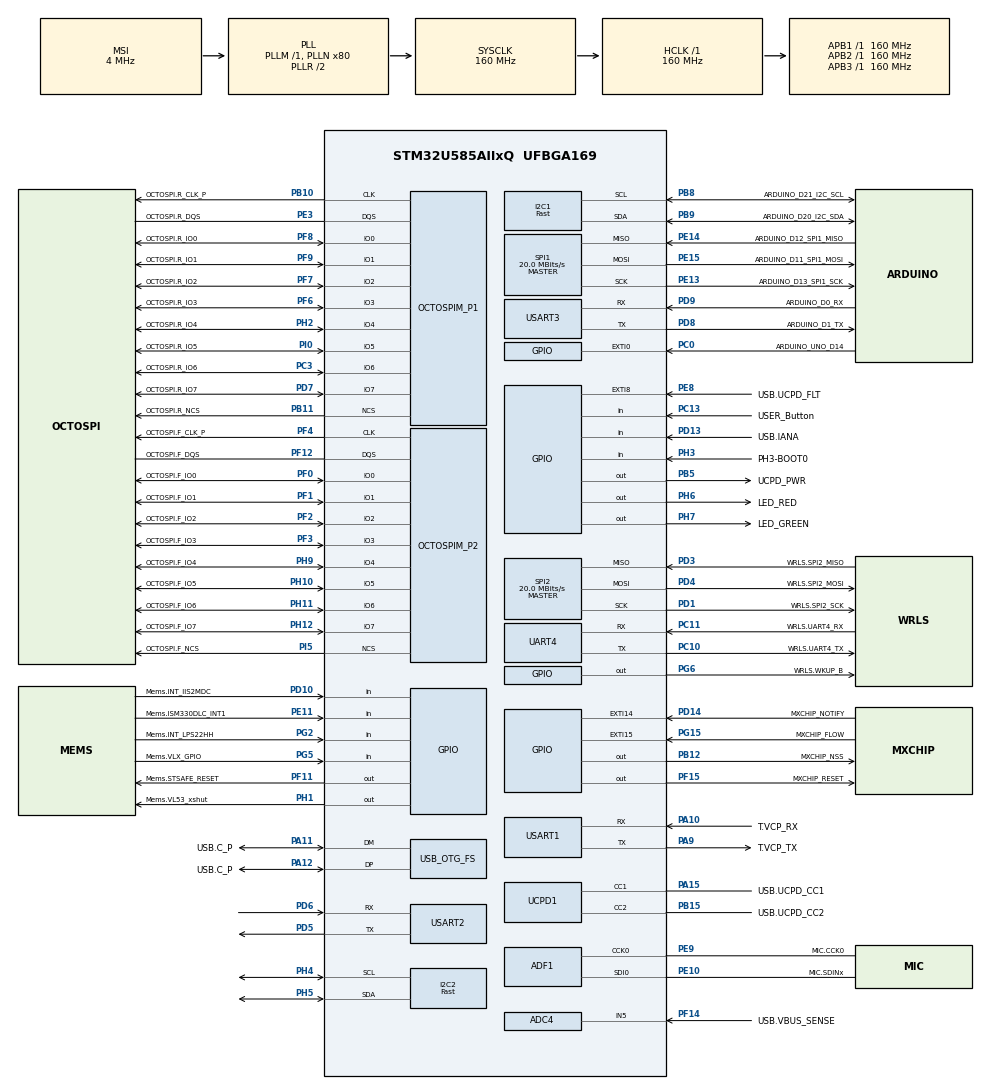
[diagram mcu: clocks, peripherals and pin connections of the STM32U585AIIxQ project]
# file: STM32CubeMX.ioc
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ADC4.NbrOfConversion=1
ADC4.NbrOfConversionFlag=0
ADC4.SelectedChannel=ADC_CHANNEL_5
CORTEX_M33_NS.userName=CORTEX_M33
GPDMA1.DESTINC_GPDMACH2=DMA_DINC_INCREMENTED
GPDMA1.DESTINC_GPDMACH4=DMA_DINC_INCREMENTED
GPDMA1.DESTINC_GPDMACH8=DMA_DINC_INCREMENTED
GPDMA1.DIRECTION_GPDMACH3=DMA_MEMORY_TO_PERIPH
GPDMA1.DIRECTION_GPDMACH5=DMA_MEMORY_TO_PERIPH
GPDMA1.DIRECTION_GPDMACH9=DMA_MEMORY_TO_PERIPH
GPDMA1.IPHANDLE_GPDMACH2-SIMPLEREQUEST_GPDMACH2=__NULL
GPDMA1.IPHANDLE_GPDMACH3-SIMPLEREQUEST_GPDMACH3=__NULL
GPDMA1.IPHANDLE_GPDMACH4-SIMPLEREQUEST_GPDMACH4=__NULL
GPDMA1.IPHANDLE_GPDMACH5-SIMPLEREQUEST_GPDMACH5=__NULL
GPDMA1.IPHANDLE_GPDMACH8-SIMPLEREQUEST_GPDMACH8=__NULL
GPDMA1.IPHANDLE_GPDMACH9-SIMPLEREQUEST_GPDMACH9=__NULL
GPDMA1.PRIORITY_GPDMACH2=DMA_LOW_PRIORITY_HIGH_WEIGHT
GPDMA1.PRIORITY_GPDMACH3=DMA_LOW_PRIORITY_HIGH_WEIGHT
GPDMA1.PRIORITY_GPDMACH4=DMA_LOW_PRIORITY_HIGH_WEIGHT
GPDMA1.PRIORITY_GPDMACH5=DMA_LOW_PRIORITY_HIGH_WEIGHT
GPDMA1.PRIORITY_GPDMACH8=DMA_LOW_PRIORITY_HIGH_WEIGHT
GPDMA1.PRIORITY_GPDMACH9=DMA_LOW_PRIORITY_HIGH_WEIGHT
GPDMA1.REQUEST_GPDMACH2=GPDMA1_REQUEST_SPI1_RX
GPDMA1.REQUEST_GPDMACH3=GPDMA1_REQUEST_SPI1_TX
GPDMA1.REQUEST_GPDMACH4=GPDMA1_REQUEST_SPI2_RX
GPDMA1.REQUEST_GPDMACH5=GPDMA1_REQUEST_SPI2_TX
GPDMA1.REQUEST_GPDMACH8=GPDMA1_REQUEST_USART3_RX
GPDMA1.REQUEST_GPDMACH9=GPDMA1_REQUEST_USART3_TX
GPDMA1.SRCINC_GPDMACH3=DMA_SINC_INCREMENTED
GPDMA1.SRCINC_GPDMACH5=DMA_SINC_INCREMENTED
GPDMA1.SRCINC_GPDMACH9=DMA_SINC_INCREMENTED
GPDMA1.TRANSFERALLOCATEDPORTDEST_GPDMACH2=DMA_DEST_ALLOCATED_PORT1
GPDMA1.TRANSFERALLOCATEDPORTDEST_GPDMACH4=DMA_DEST_ALLOCATED_PORT1
GPDMA1.TRANSFERALLOCATEDPORTDEST_GPDMACH8=DMA_DEST_ALLOCATED_PORT1
GPDMA1.TRANSFERALLOCATEDPORTSRC_GPDMACH2=DMA_SRC_ALLOCATED_PORT1
GPDMA1.TRANSFERALLOCATEDPORTSRC_GPDMACH4=DMA_SRC_ALLOCATED_PORT1
GPDMA1.TRANSFERALLOCATEDPORTSRC_GPDMACH8=DMA_SRC_ALLOCATED_PORT1
I2C1.I2C_Speed_Mode=I2C_Fast
I2C1.Timing=0x00F07BFF
I2C2.I2C_Speed_Mode=I2C_Fast
I2C2.Timing=0x00F07BFF
Mcu.Family=STM32U5
Mcu.Name=STM32U585AIIxQ
Mcu.Package=UFBGA169
NVIC.EXTI0_IRQn=true\:8\:0\:true\:false\:true\:true\:true\:true
NVIC.EXTI14_IRQn=true\:8\:0\:true\:false\:true\:true\:true\:true
NVIC.EXTI15_IRQn=true\:8\:0\:true\:false\:true\:true\:true\:true
NVIC.EXTI8_IRQn=true\:8\:0\:true\:false\:true\:true\:true\:true
NVIC.GPDMA1_Channel2_IRQn=true\:8\:0\:true\:false\:true\:false\:true\:true
NVIC.GPDMA1_Channel3_IRQn=true\:8\:0\:true\:false\:true\:false\:true\:true
NVIC.GPDMA1_Channel4_IRQn=true\:8\:0\:true\:false\:true\:false\:true\:true
NVIC.GPDMA1_Channel5_IRQn=true\:8\:0\:true\:false\:true\:false\:true\:true
NVIC.GPDMA1_Channel8_IRQn=true\:8\:0\:true\:false\:true\:false\:true\:true
NVIC.GPDMA1_Channel9_IRQn=true\:8\:0\:true\:false\:true\:false\:true\:true
NVIC.I2C1_ER_IRQn=true\:8\:0\:true\:false\:true\:true\:true\:true
NVIC.I2C1_EV_IRQn=true\:8\:0\:true\:false\:true\:true\:true\:true
NVIC.OTG_FS_IRQn=true\:8\:0\:true\:false\:true\:true\:true\:true
NVIC.PriorityGroup=NVIC_PRIORITYGROUP_4
NVIC.SPI1_IRQn=true\:8\:0\:true\:false\:true\:true\:true\:true
NVIC.SPI2_IRQn=true\:8\:0\:true\:false\:true\:true\:true\:true
NVIC.TIM17_IRQn=true\:15\:0\:false\:false\:true\:false\:true\:true
NVIC.TimeBase=TIM17_IRQn
NVIC.TimeBaseIP=TIM17
NVIC.USART1_IRQn=true\:8\:0\:true\:false\:true\:true\:true\:true
NVIC.USART2_IRQn=true\:8\:0\:true\:false\:true\:true\:true\:true
NVIC.USART3_IRQn=true\:8\:0\:true\:false\:true\:true\:true\:true
OCTOSPI1.ChipSelectBoundary=10
OCTOSPI1.ClockPrescaler=2
OCTOSPI1.DelayBlockBypass=HAL_OSPI_DELAY_BLOCK_USED
OCTOSPI1.DelayHoldQuarterCycle=HAL_OSPI_DHQC_ENABLE
OCTOSPI1.DeviceSize=23
OCTOSPI1.MemoryType=HAL_OSPI_MEMTYPE_APMEMORY
OCTOSPI1.Refresh=100
OCTOSPI2.ChipSelectBoundary=0
OCTOSPI2.ChipSelectHighTime=2
OCTOSPI2.ClockPrescaler=4
OCTOSPI2.DelayBlockBypass=HAL_OSPI_DELAY_BLOCK_USED
OCTOSPI2.DelayHoldQuarterCycle=HAL_OSPI_DHQC_ENABLE
OCTOSPI2.DeviceSize=26
OCTOSPI2.FifoThreshold=4
OCTOSPI2.MemoryType=HAL_OSPI_MEMTYPE_MACRONIX
PA10.GPIO_Label=T.VCP_RX
PA10.Mode=Asynchronous
PA10.Signal=USART1_RX
PA11.GPIO_Label=USB.C_P
PA11.GPIO_Speed=GPIO_SPEED_FREQ_HIGH
PA11.Mode=Host_Only
PA11.Signal=USB_OTG_FS_DM
PA12.GPIO_Label=USB.C_P
PA12.GPIO_Speed=GPIO_SPEED_FREQ_HIGH
PA12.Mode=Host_Only
PA12.Signal=USB_OTG_FS_DP
PA13\ (JTMS/SWDIO).GPIO_Label=T.SWDIO
PA13\ (JTMS/SWDIO).Mode=Trace_Asynchronous_SW
PA13\ (JTMS/SWDIO).Signal=DEBUG_JTMS-SWDIO
PA14\ (JTCK/SWCLK).GPIO_Label=T.SWCLK
PA14\ (JTCK/SWCLK).Mode=Trace_Asynchronous_SW
PA14\ (JTCK/SWCLK).Signal=DEBUG_JTCK-SWCLK
PA15\ (JTDI).GPIO_Label=USB.UCPD_CC1
PA15\ (JTDI).Mode=Dual_Role_AllSignals
PA15\ (JTDI).Signal=UCPD1_CC1
PA9.GPIO_Label=T.VCP_TX
PA9.Mode=Asynchronous
PA9.Signal=USART1_TX
PB1.GPIO_Label=MIC.SDIN0
PB1.Signal=MDF1_SDI0
PB10.GPIO_Label=OCTOSPI.R_CLK_P
PB10.Mode=O1_P1_CLK
PB10.Signal=OCTOSPIM_P1_CLK
PB11.GPIO_Label=OCTOSPI.R_NCS
PB11.Mode=OCTOSPI1_Port1_NCS
PB11.Signal=OCTOSPIM_P1_NCS
PB12.GPIO_Label=MXCHIP_NSS
PB12.GPIO_Speed=GPIO_SPEED_FREQ_HIGH
PB12.PinState=GPIO_PIN_SET
PB12.Signal=GPIO_Output
PB15.GPIO_Label=USB.UCPD_CC2
PB15.Mode=Dual_Role_AllSignals
PB15.Signal=UCPD1_CC2
PB3\ (JTDO/TRACESWO).GPIO_Label=T.SWO
PB3\ (JTDO/TRACESWO).Mode=Trace_Asynchronous_SW
PB3\ (JTDO/TRACESWO).Signal=DEBUG_JTDO-SWO
PB5.GPIO_Label=UCPD_PWR
PB5.Signal=GPIO_Output
PB8.GPIO_Label=ARDUINO_D21_I2C_SCL
PB8.GPIO_Pu=GPIO_NOPULL
PB8.GPIO_Speed=GPIO_SPEED_FREQ_LOW
PB8.Mode=I2C
PB8.Signal=I2C1_SCL
PB9.GPIO_Label=ARDUINO_D20_I2C_SDA
PB9.GPIO_Pu=GPIO_NOPULL
PB9.GPIO_Speed=GPIO_SPEED_FREQ_LOW
PB9.Mode=I2C
PB9.Signal=I2C1_SDA
PC0.GPIO_Label=ARDUINO_UNO_D14
PC0.Signal=GPXTI0
PC10.GPIO_Label=WRLS.UART4_TX
PC10.Mode=Asynchronous
PC10.Signal=UART4_TX
PC11.GPIO_Label=WRLS.UART4_RX
PC11.Mode=Asynchronous
PC11.Signal=UART4_RX
PC13.GPIO_Label=USER_Button
PC13.Signal=GPIO_Input
PC14-OSC32_IN\ (PC14).GPIO_Label=PC14-OSC32_IN
PC14-OSC32_IN\ (PC14).Mode=LSE-External-Oscillator
PC14-OSC32_IN\ (PC14).Signal=RCC_OSC32_IN
PC15-OSC32_OUT\ (PC15).GPIO_Label=PC15-OSC32_OUT
PC15-OSC32_OUT\ (PC15).Mode=LSE-External-Oscillator
PC15-OSC32_OUT\ (PC15).Signal=RCC_OSC32_OUT
PC3.GPIO_Label=OCTOSPI.R_IO6
PC3.Mode=OCTOSPI1_IOH_Port1H
PC3.Signal=OCTOSPIM_P1_IO6
PD1.GPIO_Label=WRLS.SPI2_SCK
PD1.GPIO_Speed=GPIO_SPEED_FREQ_HIGH
PD1.Mode=Full_Duplex_Master
PD1.Signal=SPI2_SCK
PD10.GPIO_Label=Mems.INT_IIS2MDC
PD10.Signal=GPIO_Input
PD13.GPIO_Label=USB.IANA
PD13.Signal=GPIO_Input
PD14.GPIO_Label=MXCHIP_NOTIFY
PD14.Signal=GPXTI14
PD3.GPIO_Label=WRLS.SPI2_MISO
PD3.GPIO_Speed=GPIO_SPEED_FREQ_HIGH
PD3.Mode=Full_Duplex_Master
PD3.Signal=SPI2_MISO
PD4.GPIO_Label=WRLS.SPI2_MOSI
PD4.GPIO_Speed=GPIO_SPEED_FREQ_HIGH
PD4.Mode=Full_Duplex_Master
PD4.Signal=SPI2_MOSI
PD5.Mode=Asynchronous
PD5.Signal=USART2_TX
PD6.Mode=Asynchronous
PD6.Signal=USART2_RX
PD7.GPIO_Label=OCTOSPI.R_IO7
PD7.Mode=OCTOSPI1_IOH_Port1H
PD7.Signal=OCTOSPIM_P1_IO7
PD8.GPIO_Label=ARDUINO_D1_TX
PD8.GPIO_Speed=GPIO_SPEED_FREQ_MEDIUM
PD8.Mode=Asynchronous
PD8.Signal=USART3_TX
PD9.GPIO_Label=ARDUINO_D0_RX
PD9.GPIO_Speed=GPIO_SPEED_FREQ_MEDIUM
PD9.Mode=Asynchronous
PD9.Signal=USART3_RX
PE10.GPIO_Label=MIC.SDINx
PE10.Mode=MOD_ADF_CCK
PE10.Signal=ADF1_SDI0
PE11.GPIO_Label=Mems.ISM330DLC_INT1
PE11.Signal=GPIO_Input
PE13.GPIO_Label=ARDUINO_D13_SPI1_SCK
PE13.GPIO_Speed=GPIO_SPEED_FREQ_HIGH
PE13.Mode=Full_Duplex_Master
PE13.Signal=SPI1_SCK
PE14.GPIO_Label=ARDUINO_D12_SPI1_MISO
PE14.GPIO_Speed=GPIO_SPEED_FREQ_HIGH
PE14.Mode=Full_Duplex_Master
PE14.Signal=SPI1_MISO
PE15.GPIO_Label=ARDUINO_D11_SPI1_MOSI
PE15.GPIO_Speed=GPIO_SPEED_FREQ_HIGH
PE15.Mode=Full_Duplex_Master
PE15.Signal=SPI1_MOSI
PE3.GPIO_Label=OCTOSPI.R_DQS
PE3.Mode=OCTOSPI1_Port1_DQS
PE3.Signal=OCTOSPIM_P1_DQS
PE8.GPIO_Label=USB.UCPD_FLT
PE8.GPIO_ModeDefaultEXTI=GPIO_MODE_IT_FALLING
PE8.GPIO_PuPd=GPIO_PULLUP
PE8.Signal=GPXTI8
PE9.GPIO_Label=MIC.CCK0
PE9.Mode=MOD_MDF_CCK0
PE9.Signal=ADF1_CCK0
PF0.GPIO_Label=OCTOSPI.F_IO0
PF0.Mode=OCTOSPI2_IOL_Port2L
PF0.Signal=OCTOSPIM_P2_IO0
PF1.GPIO_Label=OCTOSPI.F_IO1
PF1.Mode=OCTOSPI2_IOL_Port2L
PF1.Signal=OCTOSPIM_P2_IO1
PF10.GPIO_Label=MIC.CCK1
PF10.Signal=MDF1_CCK1
PF11.GPIO_Label=Mems.STSAFE_RESET
PF11.Signal=GPIO_Output
PF12.GPIO_Label=OCTOSPI.F_DQS
PF12.Mode=OCTOSPI2_Port2_DQS
PF12.Signal=OCTOSPIM_P2_DQS
PF14.GPIO_Label=USB.VBUS_SENSE
PF14.Signal=SharedAnalog_PF14
PF15.GPIO_Label=MXCHIP_RESET
PF15.Signal=GPIO_Output
PF2.GPIO_Label=OCTOSPI.F_IO2
PF2.Mode=OCTOSPI2_IOL_Port2L
PF2.Signal=OCTOSPIM_P2_IO2
PF3.GPIO_Label=OCTOSPI.F_IO3
PF3.Mode=OCTOSPI2_IOL_Port2L
PF3.Signal=OCTOSPIM_P2_IO3
PF4.GPIO_Label=OCTOSPI.F_CLK_P
PF4.Mode=O2_P2_CLK
PF4.Signal=OCTOSPIM_P2_CLK
PF6.GPIO_Label=OCTOSPI.R_IO3
PF6.Mode=OCTOSPI1_IOL_Port1L
PF6.Signal=OCTOSPIM_P1_IO3
PF7.GPIO_Label=OCTOSPI.R_IO2
PF7.Mode=OCTOSPI1_IOL_Port1L
PF7.Signal=OCTOSPIM_P1_IO2
PF8.GPIO_Label=OCTOSPI.R_IO0
PF8.Mode=OCTOSPI1_IOL_Port1L
PF8.Signal=OCTOSPIM_P1_IO0
PF9.GPIO_Label=OCTOSPI.R_IO1
PF9.Mode=OCTOSPI1_IOL_Port1L
PF9.Signal=OCTOSPIM_P1_IO1
PG15.GPIO_Label=MXCHIP_FLOW
PG15.Signal=GPXTI15
PG2.GPIO_Label=Mems.INT_LPS22HH
PG2.Signal=GPIO_Input
PG5.GPIO_Label=Mems.VLX_GPIO
PG5.Signal=GPIO_Input
PG6.GPIO_Label=WRLS.WKUP_B
PG6.Signal=GPIO_Output
PH1-OSC_OUT\ (PH1).GPIO_Label=Mems.VL53_xshut
PH1-OSC_OUT\ (PH1).Signal=GPIO_Output
PH10.GPIO_Label=OCTOSPI.F_IO5
PH10.Mode=OCTOSPI2_IOH_Port2H
PH10.Signal=OCTOSPIM_P2_IO5
PH11.GPIO_Label=OCTOSPI.F_IO6
PH11.Mode=OCTOSPI2_IOH_Port2H
PH11.Signal=OCTOSPIM_P2_IO6
PH12.GPIO_Label=OCTOSPI.F_IO7
PH12.Mode=OCTOSPI2_IOH_Port2H
PH12.Signal=OCTOSPIM_P2_IO7
PH2.GPIO_Label=OCTOSPI.R_IO4
PH2.Mode=OCTOSPI1_IOH_Port1H
PH2.Signal=OCTOSPIM_P1_IO4
PH3-BOOT0.GPIO_Label=PH3-BOOT0
PH3-BOOT0.Signal=GPIO_Input
PH4.Mode=I2C
PH4.Signal=I2C2_SCL
PH5.Mode=I2C
PH5.Signal=I2C2_SDA
PH6.GPIO_Label=LED_RED
PH6.Signal=GPIO_Output
PH7.GPIO_Label=LED_GREEN
PH7.Signal=GPIO_Output
PH9.GPIO_Label=OCTOSPI.F_IO4
PH9.Mode=OCTOSPI2_IOH_Port2H
PH9.Signal=OCTOSPIM_P2_IO4
PI0.GPIO_Label=OCTOSPI.R_IO5
PI0.Mode=OCTOSPI1_IOH_Port1H
PI0.Signal=OCTOSPIM_P1_IO5
PI5.GPIO_Label=OCTOSPI.F_NCS
PI5.Mode=OCTOSPI2_Port2_NCS
PI5.Signal=OCTOSPIM_P2_NCS
PWR.PowerMode=PWR_SMPS_SUPPLY
ProjectManager.HeapSize=0x10000
ProjectManager.StackSize=0x400
ProjectManager.TargetToolchain=STM32CubeIDE
RCC.ADCFreq_Value=16000000
RCC.AHBFreq_Value=160000000
RCC.APB1Freq_Value=160000000
RCC.APB1TimFreq_Value=160000000
RCC.APB2Freq_Value=160000000
RCC.APB2TimFreq_Value=160000000
RCC.APB3Freq_Value=160000000
RCC.AdfClockSelection=RCC_ADF1CLKSOURCE_PLL3
RCC.CortexFreq_Value=160000000
RCC.DACCLockSelectionVirtual=RCC_DAC1CLKSOURCE_LSI
RCC.EPOD_VALUE=4000000
RCC.HCLKFreq_Value=160000000
RCC.HSE_VALUE=16000000
RCC.HSI48_VALUE=48000000
RCC.HSI_VALUE=16000000
RCC.LSIDIV_VALUE=32000
RCC.MSI_VALUE=4000000
RCC.PLL3N=80
RCC.PLL3Q=28
RCC.PLLN=80
RCC.SYSCLKFreq_VALUE=160000000
RCC.SYSCLKSource=RCC_SYSCLKSOURCE_PLLCLK
RCC.USBFreq_Value=48000000
RCC.VCOOutputFreq_Value=320000000
SH.SharedAnalog_PF14.0=GPIO_Analog
SH.SharedAnalog_PF14.1=ADC4_IN5,IN5
SPI1.BaudRatePrescaler=SPI_BAUDRATEPRESCALER_8
SPI1.CalculateBaudRate=20.0 MBits/s
SPI1.DataSize=SPI_DATASIZE_8BIT
SPI1.Direction=SPI_DIRECTION_2LINES
SPI1.Mode=SPI_MODE_MASTER
SPI1.NSSPMode=SPI_NSS_PULSE_DISABLE
SPI1.VirtualType=VM_MASTER
SPI2.BaudRatePrescaler=SPI_BAUDRATEPRESCALER_8
SPI2.CalculateBaudRate=20.0 MBits/s
SPI2.DataSize=SPI_DATASIZE_8BIT
SPI2.Direction=SPI_DIRECTION_2LINES
SPI2.Mode=SPI_MODE_MASTER
SPI2.NSSPMode=SPI_NSS_PULSE_DISABLE
SPI2.VirtualType=VM_MASTER
USART1.VirtualMode-Asynchronous=VM_ASYNC
USART2.VirtualMode-Asynchronous=VM_ASYNC
USART3.VirtualMode-Asynchronous=VM_ASYNC
USB_OTG_FS.VirtualMode=Host_Only
USB_OTG_FS.phy_itface=HCD_PHY_EMBEDDED
VP_GPDMA1_VS_GPDMACH2.Mode=SIMPLEREQUEST_GPDMACH2
VP_GPDMA1_VS_GPDMACH3.Mode=SIMPLEREQUEST_GPDMACH3
VP_GPDMA1_VS_GPDMACH4.Mode=SIMPLEREQUEST_GPDMACH4
VP_GPDMA1_VS_GPDMACH5.Mode=SIMPLEREQUEST_GPDMACH5
VP_GPDMA1_VS_GPDMACH8.Mode=SIMPLEREQUEST_GPDMACH8
VP_GPDMA1_VS_GPDMACH9.Mode=SIMPLEREQUEST_GPDMACH9
VP_ICACHE_VS_ICACHE.Mode=DefaultMode
VP_LPBAMQUEUE_VS_QUEUE.Mode=QUEUEMODE
VP_LPBAM_VS_SIG1.Mode=SmartRun
VP_LPBAM_VS_SIG4.Mode=LPDMA1
VP_MEMORYMAP_VS_MEMORYMAP.Mode=CurAppReg
VP_OCTOSPI1_VS_octo.Mode=octo_mode
VP_OCTOSPI2_VS_octo.Mode=octo_mode
VP_PWR_VS_DBSignals.Mode=DisableDeadBatterySignals
VP_PWR_VS_LPOM.Mode=PowerOptimisation
VP_PWR_VS_SECSignals.Mode=Security/Privilege
VP_PWR_Vdda.Mode=isolationVdda
VP_SYS_VS_tim17.Mode=TIM17
board=B-U585I-IOT02A

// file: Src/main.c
/* USER CODE BEGIN Header */
/**
  ******************************************************************************
  * @file           : main.c
  * @brief          : Main program body
  ******************************************************************************
  * @note    modified by Arm
  *
  * @attention
  *
  * Copyright (c) 2024 STMicroelectronics.
  * All rights reserved.
  *
  * This software is licensed under terms that can be found in the LICENSE file
  * in the root directory of this software component.
  * If no LICENSE file comes with this software, it is provided AS-IS.
  *
  ******************************************************************************
  */
/* USER CODE END Header */
#include "main.h"

/* USER CODE BEGIN Includes */

#include "cmsis_vio.h"
#include "GPIO_STM32.h"
#include "WiFi_EMW3080.h"

#include "b_u585i_iot02a_bus.h"
#include "b_u585i_iot02a_audio.h"
#include "b_u585i_iot02a_env_sensors.h"
#include "b_u585i_iot02a_motion_sensors.h"
#include "b_u585i_iot02a_usbpd_pwr.h"

#include "ism330dhcx.h"

/* USER CODE END Includes */

ADC_HandleTypeDef hadc4;

MDF_HandleTypeDef AdfHandle0;
MDF_FilterConfigTypeDef AdfFilterConfig0;

I2C_HandleTypeDef hi2c1;
I2C_HandleTypeDef hi2c2;

OSPI_HandleTypeDef hospi1;
OSPI_HandleTypeDef hospi2;

SPI_HandleTypeDef hspi1;
SPI_HandleTypeDef hspi2;
DMA_HandleTypeDef handle_GPDMA1_Channel3;
DMA_HandleTypeDef handle_GPDMA1_Channel2;
DMA_HandleTypeDef handle_GPDMA1_Channel5;
DMA_HandleTypeDef handle_GPDMA1_Channel4;

UART_HandleTypeDef huart4;
UART_HandleTypeDef huart1;
UART_HandleTypeDef huart2;
UART_HandleTypeDef huart3;
DMA_HandleTypeDef handle_GPDMA1_Channel7;
DMA_HandleTypeDef handle_GPDMA1_Channel6;

HCD_HandleTypeDef hhcd_USB_OTG_FS;

/* USER CODE BEGIN PV */

ISM330DHCX_Object_t ISM330DHCX_Obj;

/* USER CODE END PV */

void SystemClock_Config(void);
static void SystemPower_Config(void);
static void MX_GPIO_Init(void);
static void MX_GPDMA1_Init(void);
static void MX_OCTOSPI1_Init(void);
static void MX_OCTOSPI2_Init(void);
static void MX_SPI2_Init(void);
static void MX_UART4_Init(void);
static void MX_USART1_UART_Init(void);
static void MX_ADF1_Init(void);
static void MX_USB_OTG_FS_HCD_Init(void);
static void MX_SPI1_Init(void);
static void MX_USART2_UART_Init(void);
static void MX_USART3_UART_Init(void);
static void MX_I2C1_Init(void);
static void MX_I2C2_Init(void);
static void MX_UCPD1_Init(void);
static void MX_ADC4_Init(void);
static void MX_ICACHE_Init(void);

/* USER CODE BEGIN 0 */

/* GPIO Signal Event callback */
static void GPIO_SignalEvent (ARM_GPIO_Pin_t pin, uint32_t event) {

  switch (pin) {
    case GPIO_PIN_ID_PORTD(14):                         // MXCHIP_NOTIFY pin (PD14)
      if ((event & ARM_GPIO_EVENT_RISING_EDGE) != 0U) { // If rising edge was detected
        WiFi_EMW3080_Pin_NOTIFY_Rising_Edge();
      }
      break;
    case GPIO_PIN_ID_PORTG(15):                         // MXCHIP_FLOW pin (PG15)
      if ((event & ARM_GPIO_EVENT_RISING_EDGE) != 0U) { // If rising edge was detected
        WiFi_EMW3080_Pin_FLOW_Rising_Edge();
      }
      break;
    case GPIO_PIN_ID_PORTE(8):                          // UCPD_FLT pin (PE8)
      if ((event & ARM_GPIO_EVENT_FALLING_EDGE) != 0U) {// If falling edge was detected
        BSP_USBPD_PWR_EventCallback(USBPD_PWR_TYPE_C_PORT_1);
      }
      break;
  }
}

/**
  \fn          int32_t USBH_HW_VbusOnOff (HCD_HandleTypeDef *ptr_hhcd, bool vbus)
  \brief       Hardware-specific control of VBUS line.
  \param[in]   ptr_hhcd         Pointer to hhcd
  \param[in]   vbus
                - \b false VBUS off
                - \b true  VBUS on
  \return      0 on success, -1 on error.
*/
int32_t USBH_HW_VbusOnOff (HCD_HandleTypeDef *ptr_hhcd, bool vbus) {

  if (ptr_hhcd == &hhcd_USB_OTG_FS) {
    if (vbus) {                         // VBUS power on
      BSP_USBPD_PWR_VBUSOn (USBPD_PWR_TYPE_C_PORT_1);
    } else {                            // VBUS power off
      BSP_USBPD_PWR_VBUSOff(USBPD_PWR_TYPE_C_PORT_1);
    }
  }

  return 0;
}

/* BSP Sensors Init */
static void BSP_SENSOR_Init (void) {
  ISM330DHCX_IO_t IOCtx;

  BSP_ENV_SENSOR_Init      (0U, ENV_TEMPERATURE);
  BSP_ENV_SENSOR_Init      (0U, ENV_HUMIDITY);
  BSP_ENV_SENSOR_Init      (1U, ENV_PRESSURE);
  BSP_MOTION_SENSOR_Init   (0U, MOTION_ACCELERO);
  BSP_MOTION_SENSOR_Init   (0U, MOTION_GYRO);
  BSP_MOTION_SENSOR_Init   (1U, MOTION_MAGNETO);

  BSP_ENV_SENSOR_Disable   (0U, ENV_TEMPERATURE);
  BSP_ENV_SENSOR_Disable   (0U, ENV_HUMIDITY);
  BSP_ENV_SENSOR_Disable   (1U, ENV_PRESSURE);
  BSP_MOTION_SENSOR_Disable(0U, MOTION_ACCELERO);
  BSP_MOTION_SENSOR_Disable(0U, MOTION_GYRO);
  BSP_MOTION_SENSOR_Disable(1U, MOTION_MAGNETO);

  IOCtx.BusType  = ISM330DHCX_I2C_BUS;
  IOCtx.Address  = ISM330DHCX_I2C_ADD_H;
  IOCtx.Init     = BSP_I2C2_Init;
  IOCtx.DeInit   = BSP_I2C2_DeInit;
  IOCtx.ReadReg  = BSP_I2C2_ReadReg;
  IOCtx.WriteReg = BSP_I2C2_WriteReg;
  IOCtx.GetTick  = BSP_GetTick;

  ISM330DHCX_RegisterBusIO         (&ISM330DHCX_Obj, &IOCtx);
  ISM330DHCX_Init                  (&ISM330DHCX_Obj);

  ISM330DHCX_ACC_SetFullScale      (&ISM330DHCX_Obj, ISM330DHCX_2g);
  ISM330DHCX_ACC_SetOutputDataRate (&ISM330DHCX_Obj, 1666.0f);
  ISM330DHCX_FIFO_ACC_Set_BDR      (&ISM330DHCX_Obj, 1666.0f);

  ISM330DHCX_GYRO_SetFullScale     (&ISM330DHCX_Obj, ISM330DHCX_2000dps);
  ISM330DHCX_GYRO_SetOutputDataRate(&ISM330DHCX_Obj, 1666.0f);
  ISM330DHCX_FIFO_GYRO_Set_BDR     (&ISM330DHCX_Obj, 1666.0f);

  ISM330DHCX_FIFO_Set_Mode         (&ISM330DHCX_Obj, ISM330DHCX_STREAM_MODE);
}

/* Configure SRAMs to allow non-secure/unprivileged accesses.
   This is done to enable application built for the TrustZone disabled device
   to run on the TrustZone enabled device without a dedicated Secure application.
*/
static void SRAM_Config (void) {
  GTZC_MPCBB_TypeDef *mpcbb_ptr;

  mpcbb_ptr = GTZC_MPCBB1;                      // MPCBB for SRAM1
  mpcbb_ptr->CR = GTZC_MPCBB_CR_SRWILADIS_Msk;  // Allow secure read/write access to non-secure SRAM1 block
  for (uint32_t i = 0U; i < (SRAM1_SIZE / (32*512)); i++) {
    mpcbb_ptr->SECCFGR[i]  = 0U;                // Allow non-secure access to SRAM1 super-block (32 blocks of 512 bytes)
    mpcbb_ptr->PRIVCFGR[i] = 0U;                // Allow privilieged/unprivileged access to SRAM1 super-block
  }

  mpcbb_ptr = GTZC_MPCBB2;                      // MPCBB for SRAM2
  mpcbb_ptr->CR = GTZC_MPCBB_CR_SRWILADIS_Msk;  // Allow secure read/write access to non-secure SRAM2 block
  for (uint32_t i = 0U; i < (SRAM2_SIZE / (32*512)); i++) {
    mpcbb_ptr->SECCFGR[i]  = 0U;                // Allow non-secure access to SRAM2 super-block (32 blocks of 512 bytes)
    mpcbb_ptr->PRIVCFGR[i] = 0U;                // Allow privilieged/unprivileged access to SRAM2 super-block
  }

  mpcbb_ptr = GTZC_MPCBB3;                      // MPCBB for SRAM3
  mpcbb_ptr->CR = GTZC_MPCBB_CR_SRWILADIS_Msk;  // Allow secure read/write access to non-secure SRAM3 block
  for (uint32_t i = 0U; i < (SRAM3_SIZE / (32*512)); i++) {
    mpcbb_ptr->SECCFGR[i]  = 0U;                // Allow non-secure access to SRAM3 super-block (32 blocks of 512 bytes)
    mpcbb_ptr->PRIVCFGR[i] = 0U;                // Allow privilieged/unprivileged access to SRAM3 super-block
  }

  mpcbb_ptr = GTZC_MPCBB4;                      // MPCBB for SRAM4
  mpcbb_ptr->CR = GTZC_MPCBB_CR_SRWILADIS_Msk;  // Allow secure read/write access to non-secure SRAM4 block
  for (uint32_t i = 0U; i < (SRAM4_SIZE / (32*512)); i++) {
    mpcbb_ptr->SECCFGR[i]  = 0U;                // Allow non-secure access to SRAM4 super-block (32 blocks of 512 bytes)
    mpcbb_ptr->PRIVCFGR[i] = 0U;                // Allow privilieged/unprivileged access to SRAM4 super-block
  }
}

/* USER CODE END 0 */

int main(void)
{

  /* USER CODE BEGIN 1 */

  if ((FLASH->OPTR & FLASH_OPTR_TZEN) != 0U) {  /* If TrustZone is enabled */
    SRAM_Config();                      /* Configure SRAMs to allow non-secure/unprivileged accesses */
  }

  /* USER CODE END 1 */

  /* MCU Configuration--------------------------------------------------------*/

  /* Reset of all peripherals, Initializes the Flash interface and the Systick. */
  HAL_Init();

  /* Configure the System Power */
  SystemPower_Config();

  /* Configure the system clock */
  SystemClock_Config();

  /* USER CODE BEGIN SysInit */

  SystemCoreClockUpdate();

  /* USER CODE END SysInit */

  /* Initialize all configured peripherals */
  MX_GPIO_Init();
  MX_GPDMA1_Init();
  MX_OCTOSPI1_Init();
  MX_OCTOSPI2_Init();
  MX_SPI2_Init();
  MX_UART4_Init();
  MX_USART1_UART_Init();
  MX_ADF1_Init();
  MX_USB_OTG_FS_HCD_Init();
  MX_SPI1_Init();
  MX_USART2_UART_Init();
  MX_USART3_UART_Init();
  MX_I2C1_Init();
  MX_I2C2_Init();
  MX_UCPD1_Init();
  MX_ADC4_Init();
  MX_ICACHE_Init();
  /* USER CODE BEGIN 2 */

  BSP_SENSOR_Init();                    /* Initialize on-board environment and motion sensors */

  /* Enable VBUS driving on USB Type-C Port */
  BSP_USBPD_PWR_Init        (USBPD_PWR_TYPE_C_PORT_1);
  BSP_USBPD_PWR_SetRole     (USBPD_PWR_TYPE_C_PORT_1, POWER_ROLE_SOURCE);
  BSP_USBPD_PWR_SetPowerMode(USBPD_PWR_TYPE_C_PORT_1, USBPD_PWR_MODE_NORMAL);
  BSP_USBPD_PWR_VBUSInit    (USBPD_PWR_TYPE_C_PORT_1);

  stdio_init();                         /* Initialize STDIO */

  vioInit();                            /* Initialize Virtual I/O */

#ifdef CMSIS_shield_header
  shield_setup();                       /* Setup Shield */
#endif

  app_main();                           /* Execute Application main */

  /* USER CODE END 2 */

  /* Infinite loop */
  while (1)
  {

  }
}

void SystemClock_Config(void)
{
  RCC_OscInitTypeDef RCC_OscInitStruct = {0};
  RCC_ClkInitTypeDef RCC_ClkInitStruct = {0};

  /** Configure the main internal regulator output voltage
  */
  if (HAL_PWREx_ControlVoltageScaling(PWR_REGULATOR_VOLTAGE_SCALE1) != HAL_OK)
  {
    Error_Handler();
  }

  /** Initializes the CPU, AHB and APB buses clocks
  */
  RCC_OscInitStruct.OscillatorType = RCC_OSCILLATORTYPE_HSI48|RCC_OSCILLATORTYPE_HSI
                              |RCC_OSCILLATORTYPE_MSI;
  RCC_OscInitStruct.HSIState = RCC_HSI_ON;
  RCC_OscInitStruct.HSI48State = RCC_HSI48_ON;
  RCC_OscInitStruct.HSICalibrationValue = RCC_HSICALIBRATION_DEFAULT;
  RCC_OscInitStruct.MSIState = RCC_MSI_ON;
  RCC_OscInitStruct.MSICalibrationValue = RCC_MSICALIBRATION_DEFAULT;
  RCC_OscInitStruct.MSIClockRange = RCC_MSIRANGE_4;
  RCC_OscInitStruct.PLL.PLLState = RCC_PLL_ON;
  RCC_OscInitStruct.PLL.PLLSource = RCC_PLLSOURCE_MSI;
  RCC_OscInitStruct.PLL.PLLMBOOST = RCC_PLLMBOOST_DIV1;
  RCC_OscInitStruct.PLL.PLLM = 1;
  RCC_OscInitStruct.PLL.PLLN = 80;
  RCC_OscInitStruct.PLL.PLLP = 2;
  RCC_OscInitStruct.PLL.PLLQ = 2;
  RCC_OscInitStruct.PLL.PLLR = 2;
  RCC_OscInitStruct.PLL.PLLRGE = RCC_PLLVCIRANGE_0;
  RCC_OscInitStruct.PLL.PLLFRACN = 0;
  if (HAL_RCC_OscConfig(&RCC_OscInitStruct) != HAL_OK)
  {
    Error_Handler();
  }

  /** Initializes the CPU, AHB and APB buses clocks
  */
  RCC_ClkInitStruct.ClockType = RCC_CLOCKTYPE_HCLK|RCC_CLOCKTYPE_SYSCLK
                              |RCC_CLOCKTYPE_PCLK1|RCC_CLOCKTYPE_PCLK2
                              |RCC_CLOCKTYPE_PCLK3;
  RCC_ClkInitStruct.SYSCLKSource = RCC_SYSCLKSOURCE_PLLCLK;
  RCC_ClkInitStruct.AHBCLKDivider = RCC_SYSCLK_DIV1;
  RCC_ClkInitStruct.APB1CLKDivider = RCC_HCLK_DIV1;
  RCC_ClkInitStruct.APB2CLKDivider = RCC_HCLK_DIV1;
  RCC_ClkInitStruct.APB3CLKDivider = RCC_HCLK_DIV1;

  if (HAL_RCC_ClockConfig(&RCC_ClkInitStruct, FLASH_LATENCY_4) != HAL_OK)
  {
    Error_Handler();
  }
}

/**
  * @brief Power Configuration
  * @retval None
  */
static void SystemPower_Config(void)
{
  HAL_PWREx_EnableVddIO2();

  /*
   * Switch to SMPS regulator instead of LDO
   */
  if (HAL_PWREx_ConfigSupply(PWR_SMPS_SUPPLY) != HAL_OK)
  {
    Error_Handler();
  }
}

static void MX_ADC4_Init(void)
{

  ADC_ChannelConfTypeDef sConfig = {0};

  /** Common config
  */
  hadc4.Instance = ADC4;
  hadc4.Init.ClockPrescaler = ADC_CLOCK_ASYNC_DIV1;
  hadc4.Init.Resolution = ADC_RESOLUTION_12B;
  hadc4.Init.DataAlign = ADC_DATAALIGN_RIGHT;
  hadc4.Init.ScanConvMode = ADC_SCAN_DIRECTION_FORWARD;
  hadc4.Init.EOCSelection = ADC_EOC_SINGLE_CONV;
  hadc4.Init.LowPowerAutoPowerOff = ADC_LOW_POWER_NONE;
  hadc4.Init.LowPowerAutoWait = DISABLE;
  hadc4.Init.ContinuousConvMode = DISABLE;
  hadc4.Init.NbrOfConversion = 1;
  hadc4.Init.DiscontinuousConvMode = DISABLE;
  hadc4.Init.ExternalTrigConv = ADC_SOFTWARE_START;
  hadc4.Init.ExternalTrigConvEdge = ADC_EXTERNALTRIGCONVEDGE_NONE;
  hadc4.Init.DMAContinuousRequests = DISABLE;
  hadc4.Init.TriggerFrequencyMode = ADC_TRIGGER_FREQ_LOW;
  hadc4.Init.Overrun = ADC_OVR_DATA_PRESERVED;
  hadc4.Init.SamplingTimeCommon1 = ADC4_SAMPLETIME_1CYCLE_5;
  hadc4.Init.SamplingTimeCommon2 = ADC4_SAMPLETIME_1CYCLE_5;
  hadc4.Init.OversamplingMode = DISABLE;
  if (HAL_ADC_Init(&hadc4) != HAL_OK)
  {
    Error_Handler();
  }

  /** Configure Regular Channel
  */
  sConfig.Channel = ADC_CHANNEL_5;
  sConfig.Rank = ADC4_RANK_CHANNEL_NUMBER;
  sConfig.SamplingTime = ADC4_SAMPLINGTIME_COMMON_1;
  sConfig.OffsetNumber = ADC_OFFSET_NONE;
  sConfig.Offset = 0;
  if (HAL_ADC_ConfigChannel(&hadc4, &sConfig) != HAL_OK)
  {
    Error_Handler();
  }

}

static void MX_ADF1_Init(void)
{

  /**
    AdfHandle0 structure initialization and HAL_MDF_Init function call
  */
  AdfHandle0.Instance = ADF1_Filter0;
  AdfHandle0.Init.CommonParam.ProcClockDivider = 1;
  AdfHandle0.Init.CommonParam.OutputClock.Activation = DISABLE;
  AdfHandle0.Init.SerialInterface.Activation = ENABLE;
  AdfHandle0.Init.SerialInterface.Mode = MDF_SITF_LF_MASTER_SPI_MODE;
  AdfHandle0.Init.SerialInterface.ClockSource = MDF_SITF_CCK0_SOURCE;
  AdfHandle0.Init.SerialInterface.Threshold = 4;
  AdfHandle0.Init.FilterBistream = MDF_BITSTREAM0_FALLING;
  if (HAL_MDF_Init(&AdfHandle0) != HAL_OK)
  {
    Error_Handler();
  }

  /**
    AdfFilterConfig0 structure initialization

    WARNING : only structure is filled, no specific init function call for filter
  */
  AdfFilterConfig0.DataSource = MDF_DATA_SOURCE_BSMX;
  AdfFilterConfig0.Delay = 0;
  AdfFilterConfig0.CicMode = MDF_ONE_FILTER_SINC4;
  AdfFilterConfig0.DecimationRatio = 2;
  AdfFilterConfig0.Gain = 0;
  AdfFilterConfig0.ReshapeFilter.Activation = DISABLE;
  AdfFilterConfig0.HighPassFilter.Activation = DISABLE;
  AdfFilterConfig0.SoundActivity.Activation = DISABLE;
  AdfFilterConfig0.AcquisitionMode = MDF_MODE_ASYNC_CONT;
  AdfFilterConfig0.FifoThreshold = MDF_FIFO_THRESHOLD_NOT_EMPTY;
  AdfFilterConfig0.DiscardSamples = 0;

}

static void MX_GPDMA1_Init(void)
{

  /* Peripheral clock enable */
  __HAL_RCC_GPDMA1_CLK_ENABLE();

  /* GPDMA1 interrupt Init */
    HAL_NVIC_SetPriority(GPDMA1_Channel2_IRQn, 8, 0);
    HAL_NVIC_EnableIRQ(GPDMA1_Channel2_IRQn);
    HAL_NVIC_SetPriority(GPDMA1_Channel3_IRQn, 8, 0);
    HAL_NVIC_EnableIRQ(GPDMA1_Channel3_IRQn);
    HAL_NVIC_SetPriority(GPDMA1_Channel4_IRQn, 8, 0);
    HAL_NVIC_EnableIRQ(GPDMA1_Channel4_IRQn);
    HAL_NVIC_SetPriority(GPDMA1_Channel5_IRQn, 8, 0);
    HAL_NVIC_EnableIRQ(GPDMA1_Channel5_IRQn);
    HAL_NVIC_SetPriority(GPDMA1_Channel6_IRQn, 8, 0);
    HAL_NVIC_EnableIRQ(GPDMA1_Channel6_IRQn);
    HAL_NVIC_SetPriority(GPDMA1_Channel7_IRQn, 8, 0);
    HAL_NVIC_EnableIRQ(GPDMA1_Channel7_IRQn);

}

static void MX_I2C1_Init(void)
{

  hi2c1.Instance = I2C1;
  hi2c1.Init.Timing = 0x00F07BFF;
  hi2c1.Init.OwnAddress1 = 0;
  hi2c1.Init.AddressingMode = I2C_ADDRESSINGMODE_7BIT;
  hi2c1.Init.DualAddressMode = I2C_DUALADDRESS_DISABLE;
  hi2c1.Init.OwnAddress2 = 0;
  hi2c1.Init.OwnAddress2Masks = I2C_OA2_NOMASK;
  hi2c1.Init.GeneralCallMode = I2C_GENERALCALL_DISABLE;
  hi2c1.Init.NoStretchMode = I2C_NOSTRETCH_DISABLE;
  if (HAL_I2C_Init(&hi2c1) != HAL_OK)
  {
    Error_Handler();
  }

  /** Configure Analogue filter
  */
  if (HAL_I2CEx_ConfigAnalogFilter(&hi2c1, I2C_ANALOGFILTER_ENABLE) != HAL_OK)
  {
    Error_Handler();
  }

  /** Configure Digital filter
  */
  if (HAL_I2CEx_ConfigDigitalFilter(&hi2c1, 0) != HAL_OK)
  {
    Error_Handler();
  }

}

static void MX_I2C2_Init(void)
{

  hi2c2.Instance = I2C2;
  hi2c2.Init.Timing = 0x00F07BFF;
  hi2c2.Init.OwnAddress1 = 0;
  hi2c2.Init.AddressingMode = I2C_ADDRESSINGMODE_7BIT;
  hi2c2.Init.DualAddressMode = I2C_DUALADDRESS_DISABLE;
  hi2c2.Init.OwnAddress2 = 0;
  hi2c2.Init.OwnAddress2Masks = I2C_OA2_NOMASK;
  hi2c2.Init.GeneralCallMode = I2C_GENERALCALL_DISABLE;
  hi2c2.Init.NoStretchMode = I2C_NOSTRETCH_DISABLE;
  if (HAL_I2C_Init(&hi2c2) != HAL_OK)
  {
    Error_Handler();
  }

  /** Configure Analogue filter
  */
  if (HAL_I2CEx_ConfigAnalogFilter(&hi2c2, I2C_ANALOGFILTER_ENABLE) != HAL_OK)
  {
    Error_Handler();
  }

  /** Configure Digital filter
  */
  if (HAL_I2CEx_ConfigDigitalFilter(&hi2c2, 0) != HAL_OK)
  {
    Error_Handler();
  }

}

static void MX_ICACHE_Init(void)
{

  /** Enable instruction cache (default 2-ways set associative cache)
  */
  if (HAL_ICACHE_Enable() != HAL_OK)
  {
    Error_Handler();
  }

}

static void MX_OCTOSPI1_Init(void)
{

  OSPIM_CfgTypeDef sOspiManagerCfg = {0};
  HAL_OSPI_DLYB_CfgTypeDef HAL_OSPI_DLYB_Cfg_Struct = {0};

  /* OCTOSPI1 parameter configuration*/
  hospi1.Instance = OCTOSPI1;
  hospi1.Init.FifoThreshold = 1;
  hospi1.Init.DualQuad = HAL_OSPI_DUALQUAD_DISABLE;
  hospi1.Init.MemoryType = HAL_OSPI_MEMTYPE_APMEMORY;
  hospi1.Init.DeviceSize = 23;
  hospi1.Init.ChipSelectHighTime = 1;
  hospi1.Init.FreeRunningClock = HAL_OSPI_FREERUNCLK_DISABLE;
  hospi1.Init.ClockMode = HAL_OSPI_CLOCK_MODE_0;
  hospi1.Init.WrapSize = HAL_OSPI_WRAP_NOT_SUPPORTED;
  hospi1.Init.ClockPrescaler = 2;
  hospi1.Init.SampleShifting = HAL_OSPI_SAMPLE_SHIFTING_NONE;
  hospi1.Init.DelayHoldQuarterCycle = HAL_OSPI_DHQC_ENABLE;
  hospi1.Init.ChipSelectBoundary = 10;
  hospi1.Init.DelayBlockBypass = HAL_OSPI_DELAY_BLOCK_USED;
  hospi1.Init.MaxTran = 0;
  hospi1.Init.Refresh = 100;
  if (HAL_OSPI_Init(&hospi1) != HAL_OK)
  {
    Error_Handler();
  }
  sOspiManagerCfg.ClkPort = 1;
  sOspiManagerCfg.DQSPort = 1;
  sOspiManagerCfg.NCSPort = 1;
  sOspiManagerCfg.IOLowPort = HAL_OSPIM_IOPORT_1_LOW;
  sOspiManagerCfg.IOHighPort = HAL_OSPIM_IOPORT_1_HIGH;
  if (HAL_OSPIM_Config(&hospi1, &sOspiManagerCfg, HAL_OSPI_TIMEOUT_DEFAULT_VALUE) != HAL_OK)
  {
    Error_Handler();
  }
  HAL_OSPI_DLYB_Cfg_Struct.Units = 0;
  HAL_OSPI_DLYB_Cfg_Struct.PhaseSel = 0;
  if (HAL_OSPI_DLYB_SetConfig(&hospi1, &HAL_OSPI_DLYB_Cfg_Struct) != HAL_OK)
  {
    Error_Handler();
  }

}

static void MX_OCTOSPI2_Init(void)
{

  OSPIM_CfgTypeDef sOspiManagerCfg = {0};
  HAL_OSPI_DLYB_CfgTypeDef HAL_OSPI_DLYB_Cfg_Struct = {0};

  /* OCTOSPI2 parameter configuration*/
  hospi2.Instance = OCTOSPI2;
  hospi2.Init.FifoThreshold = 4;
  hospi2.Init.DualQuad = HAL_OSPI_DUALQUAD_DISABLE;
  hospi2.Init.MemoryType = HAL_OSPI_MEMTYPE_MACRONIX;
  hospi2.Init.DeviceSize = 26;
  hospi2.Init.ChipSelectHighTime = 2;
  hospi2.Init.FreeRunningClock = HAL_OSPI_FREERUNCLK_DISABLE;
  hospi2.Init.ClockMode = HAL_OSPI_CLOCK_MODE_0;
  hospi2.Init.WrapSize = HAL_OSPI_WRAP_NOT_SUPPORTED;
  hospi2.Init.ClockPrescaler = 4;
  hospi2.Init.SampleShifting = HAL_OSPI_SAMPLE_SHIFTING_NONE;
  hospi2.Init.DelayHoldQuarterCycle = HAL_OSPI_DHQC_ENABLE;
  hospi2.Init.ChipSelectBoundary = 0;
  hospi2.Init.DelayBlockBypass = HAL_OSPI_DELAY_BLOCK_USED;
  hospi2.Init.MaxTran = 0;
  hospi2.Init.Refresh = 0;
  if (HAL_OSPI_Init(&hospi2) != HAL_OK)
  {
    Error_Handler();
  }
  sOspiManagerCfg.ClkPort = 2;
  sOspiManagerCfg.DQSPort = 2;
  sOspiManagerCfg.NCSPort = 2;
  sOspiManagerCfg.IOLowPort = HAL_OSPIM_IOPORT_2_LOW;
  sOspiManagerCfg.IOHighPort = HAL_OSPIM_IOPORT_2_HIGH;
  if (HAL_OSPIM_Config(&hospi2, &sOspiManagerCfg, HAL_OSPI_TIMEOUT_DEFAULT_VALUE) != HAL_OK)
  {
    Error_Handler();
  }
  HAL_OSPI_DLYB_Cfg_Struct.Units = 0;
  HAL_OSPI_DLYB_Cfg_Struct.PhaseSel = 0;
  if (HAL_OSPI_DLYB_SetConfig(&hospi2, &HAL_OSPI_DLYB_Cfg_Struct) != HAL_OK)
  {
    Error_Handler();
  }

}

static void MX_SPI1_Init(void)
{

  SPI_AutonomousModeConfTypeDef HAL_SPI_AutonomousMode_Cfg_Struct = {0};

  /* SPI1 parameter configuration*/
  hspi1.Instance = SPI1;
  hspi1.Init.Mode = SPI_MODE_MASTER;
  hspi1.Init.Direction = SPI_DIRECTION_2LINES;
  hspi1.Init.DataSize = SPI_DATASIZE_8BIT;
  hspi1.Init.CLKPolarity = SPI_POLARITY_LOW;
  hspi1.Init.CLKPhase = SPI_PHASE_1EDGE;
  hspi1.Init.NSS = SPI_NSS_SOFT;
  hspi1.Init.BaudRatePrescaler = SPI_BAUDRATEPRESCALER_8;
  hspi1.Init.FirstBit = SPI_FIRSTBIT_MSB;
  hspi1.Init.TIMode = SPI_TIMODE_DISABLE;
  hspi1.Init.CRCCalculation = SPI_CRCCALCULATION_DISABLE;
  hspi1.Init.CRCPolynomial = 0x7;
  hspi1.Init.NSSPMode = SPI_NSS_PULSE_DISABLE;
  hspi1.Init.NSSPolarity = SPI_NSS_POLARITY_LOW;
  hspi1.Init.FifoThreshold = SPI_FIFO_THRESHOLD_01DATA;
  hspi1.Init.MasterSSIdleness = SPI_MASTER_SS_IDLENESS_00CYCLE;
  hspi1.Init.MasterInterDataIdleness = SPI_MASTER_INTERDATA_IDLENESS_00CYCLE;
  hspi1.Init.MasterReceiverAutoSusp = SPI_MASTER_RX_AUTOSUSP_DISABLE;
  hspi1.Init.MasterKeepIOState = SPI_MASTER_KEEP_IO_STATE_DISABLE;
  hspi1.Init.IOSwap = SPI_IO_SWAP_DISABLE;
  hspi1.Init.ReadyMasterManagement = SPI_RDY_MASTER_MANAGEMENT_INTERNALLY;
  hspi1.Init.ReadyPolarity = SPI_RDY_POLARITY_HIGH;
  if (HAL_SPI_Init(&hspi1) != HAL_OK)
  {
    Error_Handler();
  }
  HAL_SPI_AutonomousMode_Cfg_Struct.TriggerState = SPI_AUTO_MODE_DISABLE;
  HAL_SPI_AutonomousMode_Cfg_Struct.TriggerSelection = SPI_GRP1_GPDMA_CH0_TCF_TRG;
  HAL_SPI_AutonomousMode_Cfg_Struct.TriggerPolarity = SPI_TRIG_POLARITY_RISING;
  if (HAL_SPIEx_SetConfigAutonomousMode(&hspi1, &HAL_SPI_AutonomousMode_Cfg_Struct) != HAL_OK)
  {
    Error_Handler();
  }

}

static void MX_SPI2_Init(void)
{

  SPI_AutonomousModeConfTypeDef HAL_SPI_AutonomousMode_Cfg_Struct = {0};

  /* SPI2 parameter configuration*/
  hspi2.Instance = SPI2;
  hspi2.Init.Mode = SPI_MODE_MASTER;
  hspi2.Init.Direction = SPI_DIRECTION_2LINES;
  hspi2.Init.DataSize = SPI_DATASIZE_8BIT;
  hspi2.Init.CLKPolarity = SPI_POLARITY_LOW;
  hspi2.Init.CLKPhase = SPI_PHASE_1EDGE;
  hspi2.Init.NSS = SPI_NSS_SOFT;
  hspi2.Init.BaudRatePrescaler = SPI_BAUDRATEPRESCALER_8;
  hspi2.Init.FirstBit = SPI_FIRSTBIT_MSB;
  hspi2.Init.TIMode = SPI_TIMODE_DISABLE;
  hspi2.Init.CRCCalculation = SPI_CRCCALCULATION_DISABLE;
  hspi2.Init.CRCPolynomial = 0x7;
  hspi2.Init.NSSPMode = SPI_NSS_PULSE_DISABLE;
  hspi2.Init.NSSPolarity = SPI_NSS_POLARITY_LOW;
  hspi2.Init.FifoThreshold = SPI_FIFO_THRESHOLD_01DATA;
  hspi2.Init.MasterSSIdleness = SPI_MASTER_SS_IDLENESS_00CYCLE;
  hspi2.Init.MasterInterDataIdleness = SPI_MASTER_INTERDATA_IDLENESS_00CYCLE;
  hspi2.Init.MasterReceiverAutoSusp = SPI_MASTER_RX_AUTOSUSP_DISABLE;
  hspi2.Init.MasterKeepIOState = SPI_MASTER_KEEP_IO_STATE_DISABLE;
  hspi2.Init.IOSwap = SPI_IO_SWAP_DISABLE;
  hspi2.Init.ReadyMasterManagement = SPI_RDY_MASTER_MANAGEMENT_INTERNALLY;
  hspi2.Init.ReadyPolarity = SPI_RDY_POLARITY_HIGH;
  if (HAL_SPI_Init(&hspi2) != HAL_OK)
  {
    Error_Handler();
  }
  HAL_SPI_AutonomousMode_Cfg_Struct.TriggerState = SPI_AUTO_MODE_DISABLE;
  HAL_SPI_AutonomousMode_Cfg_Struct.TriggerSelection = SPI_GRP1_GPDMA_CH0_TCF_TRG;
  HAL_SPI_AutonomousMode_Cfg_Struct.TriggerPolarity = SPI_TRIG_POLARITY_RISING;
  if (HAL_SPIEx_SetConfigAutonomousMode(&hspi2, &HAL_SPI_AutonomousMode_Cfg_Struct) != HAL_OK)
  {
    Error_Handler();
  }

}

static void MX_UART4_Init(void)
{

  huart4.Instance = UART4;
  huart4.Init.BaudRate = 115200;
  huart4.Init.WordLength = UART_WORDLENGTH_8B;
  huart4.Init.StopBits = UART_STOPBITS_1;
  huart4.Init.Parity = UART_PARITY_NONE;
  huart4.Init.Mode = UART_MODE_TX_RX;
  huart4.Init.HwFlowCtl = UART_HWCONTROL_NONE;
  huart4.Init.OverSampling = UART_OVERSAMPLING_16;
  huart4.Init.OneBitSampling = UART_ONE_BIT_SAMPLE_DISABLE;
  huart4.Init.ClockPrescaler = UART_PRESCALER_DIV1;
  huart4.AdvancedInit.AdvFeatureInit = UART_ADVFEATURE_NO_INIT;
  if (HAL_UART_Init(&huart4) != HAL_OK)
  {
    Error_Handler();
  }
  if (HAL_UARTEx_SetTxFifoThreshold(&huart4, UART_TXFIFO_THRESHOLD_1_8) != HAL_OK)
  {
    Error_Handler();
  }
  if (HAL_UARTEx_SetRxFifoThreshold(&huart4, UART_RXFIFO_THRESHOLD_1_8) != HAL_OK)
  {
    Error_Handler();
  }
  if (HAL_UARTEx_DisableFifoMode(&huart4) != HAL_OK)
  {
    Error_Handler();
  }

}

static void MX_USART1_UART_Init(void)
{

  huart1.Instance = USART1;
  huart1.Init.BaudRate = 115200;
  huart1.Init.WordLength = UART_WORDLENGTH_8B;
  huart1.Init.StopBits = UART_STOPBITS_1;
  huart1.Init.Parity = UART_PARITY_NONE;
  huart1.Init.Mode = UART_MODE_TX_RX;
  huart1.Init.HwFlowCtl = UART_HWCONTROL_NONE;
  huart1.Init.OverSampling = UART_OVERSAMPLING_16;
  huart1.Init.OneBitSampling = UART_ONE_BIT_SAMPLE_DISABLE;
  huart1.Init.ClockPrescaler = UART_PRESCALER_DIV1;
  huart1.AdvancedInit.AdvFeatureInit = UART_ADVFEATURE_NO_INIT;
  if (HAL_UART_Init(&huart1) != HAL_OK)
  {
    Error_Handler();
  }
  if (HAL_UARTEx_SetTxFifoThreshold(&huart1, UART_TXFIFO_THRESHOLD_1_8) != HAL_OK)
  {
    Error_Handler();
  }
  if (HAL_UARTEx_SetRxFifoThreshold(&huart1, UART_RXFIFO_THRESHOLD_1_8) != HAL_OK)
  {
    Error_Handler();
  }
  if (HAL_UARTEx_DisableFifoMode(&huart1) != HAL_OK)
  {
    Error_Handler();
  }

}

static void MX_USART2_UART_Init(void)
{

  huart2.Instance = USART2;
  huart2.Init.BaudRate = 115200;
  huart2.Init.WordLength = UART_WORDLENGTH_8B;
  huart2.Init.StopBits = UART_STOPBITS_1;
  huart2.Init.Parity = UART_PARITY_NONE;
  huart2.Init.Mode = UART_MODE_TX_RX;
  huart2.Init.HwFlowCtl = UART_HWCONTROL_NONE;
  huart2.Init.OverSampling = UART_OVERSAMPLING_16;
  huart2.Init.OneBitSampling = UART_ONE_BIT_SAMPLE_DISABLE;
  huart2.Init.ClockPrescaler = UART_PRESCALER_DIV1;
  huart2.AdvancedInit.AdvFeatureInit = UART_ADVFEATURE_NO_INIT;
  if (HAL_UART_Init(&huart2) != HAL_OK)
  {
    Error_Handler();
  }
  if (HAL_UARTEx_SetTxFifoThreshold(&huart2, UART_TXFIFO_THRESHOLD_1_8) != HAL_OK)
  {
    Error_Handler();
  }
  if (HAL_UARTEx_SetRxFifoThreshold(&huart2, UART_RXFIFO_THRESHOLD_1_8) != HAL_OK)
  {
    Error_Handler();
  }
  if (HAL_UARTEx_DisableFifoMode(&huart2) != HAL_OK)
  {
    Error_Handler();
  }

}

static void MX_USART3_UART_Init(void)
{

  huart3.Instance = USART3;
  huart3.Init.BaudRate = 115200;
  huart3.Init.WordLength = UART_WORDLENGTH_8B;
  huart3.Init.StopBits = UART_STOPBITS_1;
  huart3.Init.Parity = UART_PARITY_NONE;
  huart3.Init.Mode = UART_MODE_TX_RX;
  huart3.Init.HwFlowCtl = UART_HWCONTROL_NONE;
  huart3.Init.OverSampling = UART_OVERSAMPLING_16;
  huart3.Init.OneBitSampling = UART_ONE_BIT_SAMPLE_DISABLE;
  huart3.Init.ClockPrescaler = UART_PRESCALER_DIV1;
  huart3.AdvancedInit.AdvFeatureInit = UART_ADVFEATURE_NO_INIT;
  if (HAL_UART_Init(&huart3) != HAL_OK)
  {
    Error_Handler();
  }
  if (HAL_UARTEx_SetTxFifoThreshold(&huart3, UART_TXFIFO_THRESHOLD_1_8) != HAL_OK)
  {
    Error_Handler();
  }
  if (HAL_UARTEx_SetRxFifoThreshold(&huart3, UART_RXFIFO_THRESHOLD_1_8) != HAL_OK)
  {
    Error_Handler();
  }
  if (HAL_UARTEx_DisableFifoMode(&huart3) != HAL_OK)
  {
    Error_Handler();
  }

}

static void MX_UCPD1_Init(void)
{

  LL_GPIO_InitTypeDef GPIO_InitStruct = {0};

  /* Peripheral clock enable */
  LL_APB1_GRP2_EnableClock(LL_APB1_GRP2_PERIPH_UCPD1);

  LL_AHB2_GRP1_EnableClock(LL_AHB2_GRP1_PERIPH_GPIOA);
  LL_AHB2_GRP1_EnableClock(LL_AHB2_GRP1_PERIPH_GPIOB);
  /**UCPD1 GPIO Configuration
  PA15 (JTDI)   ------> UCPD1_CC1
  PB15   ------> UCPD1_CC2
  */
  GPIO_InitStruct.Pin = LL_GPIO_PIN_15;
  GPIO_InitStruct.Mode = LL_GPIO_MODE_ANALOG;
  GPIO_InitStruct.Pull = LL_GPIO_PULL_NO;
  LL_GPIO_Init(GPIOA, &GPIO_InitStruct);

  GPIO_InitStruct.Pin = LL_GPIO_PIN_15;
  GPIO_InitStruct.Mode = LL_GPIO_MODE_ANALOG;
  GPIO_InitStruct.Pull = LL_GPIO_PULL_NO;
  LL_GPIO_Init(GPIOB, &GPIO_InitStruct);

}

static void MX_USB_OTG_FS_HCD_Init(void)
{

  hhcd_USB_OTG_FS.Instance = USB_OTG_FS;
  hhcd_USB_OTG_FS.Init.Host_channels = 12;
  hhcd_USB_OTG_FS.Init.speed = HCD_SPEED_FULL;
  hhcd_USB_OTG_FS.Init.dma_enable = DISABLE;
  hhcd_USB_OTG_FS.Init.phy_itface = HCD_PHY_EMBEDDED;
  hhcd_USB_OTG_FS.Init.Sof_enable = DISABLE;
  hhcd_USB_OTG_FS.Init.vbus_sensing_enable = DISABLE;
  if (HAL_HCD_Init(&hhcd_USB_OTG_FS) != HAL_OK)
  {
    Error_Handler();
  }

}

static void MX_GPIO_Init(void)
{
  GPIO_InitTypeDef GPIO_InitStruct = {0};

  /* GPIO Ports Clock Enable */
  __HAL_RCC_GPIOG_CLK_ENABLE();
  __HAL_RCC_GPIOC_CLK_ENABLE();
  __HAL_RCC_GPIOA_CLK_ENABLE();
  __HAL_RCC_GPIOI_CLK_ENABLE();
  __HAL_RCC_GPIOD_CLK_ENABLE();
  __HAL_RCC_GPIOH_CLK_ENABLE();
  __HAL_RCC_GPIOB_CLK_ENABLE();
  __HAL_RCC_GPIOE_CLK_ENABLE();
  __HAL_RCC_GPIOF_CLK_ENABLE();

  /*Configure GPIO pin Output Level */
  HAL_GPIO_WritePin(UCPD_PWR_GPIO_Port, UCPD_PWR_Pin, GPIO_PIN_RESET);

  /*Configure GPIO pin Output Level */
  HAL_GPIO_WritePin(GPIOH, LED_RED_Pin|LED_GREEN_Pin|Mems_VL53_xshut_Pin, GPIO_PIN_RESET);

  /*Configure GPIO pin Output Level */
  HAL_GPIO_WritePin(WRLS_WKUP_B_GPIO_Port, WRLS_WKUP_B_Pin, GPIO_PIN_RESET);

  /*Configure GPIO pin Output Level */
  HAL_GPIO_WritePin(MXCHIP_NSS_GPIO_Port, MXCHIP_NSS_Pin, GPIO_PIN_SET);

  /*Configure GPIO pin Output Level */
  HAL_GPIO_WritePin(GPIOF, Mems_STSAFE_RESET_Pin|MXCHIP_RESET_Pin, GPIO_PIN_RESET);

  /*Configure GPIO pin : MXCHIP_FLOW_Pin */
  GPIO_InitStruct.Pin = MXCHIP_FLOW_Pin;
  GPIO_InitStruct.Mode = GPIO_MODE_IT_RISING;
  GPIO_InitStruct.Pull = GPIO_NOPULL;
  HAL_GPIO_Init(MXCHIP_FLOW_GPIO_Port, &GPIO_InitStruct);

  /*Configure GPIO pin : PH3_BOOT0_Pin */
  GPIO_InitStruct.Pin = PH3_BOOT0_Pin;
  GPIO_InitStruct.Mode = GPIO_MODE_INPUT;
  GPIO_InitStruct.Pull = GPIO_NOPULL;
  HAL_GPIO_Init(PH3_BOOT0_GPIO_Port, &GPIO_InitStruct);

  /*Configure GPIO pin : UCPD_PWR_Pin */
  GPIO_InitStruct.Pin = UCPD_PWR_Pin;
  GPIO_InitStruct.Mode = GPIO_MODE_OUTPUT_PP;
  GPIO_InitStruct.Pull = GPIO_NOPULL;
  GPIO_InitStruct.Speed = GPIO_SPEED_FREQ_LOW;
  HAL_GPIO_Init(UCPD_PWR_GPIO_Port, &GPIO_InitStruct);

  /*Configure GPIO pin : USER_Button_Pin */
  GPIO_InitStruct.Pin = USER_Button_Pin;
  GPIO_InitStruct.Mode = GPIO_MODE_INPUT;
  GPIO_InitStruct.Pull = GPIO_NOPULL;
  HAL_GPIO_Init(USER_Button_GPIO_Port, &GPIO_InitStruct);

  /*Configure GPIO pins : LED_RED_Pin LED_GREEN_Pin Mems_VL53_xshut_Pin */
  GPIO_InitStruct.Pin = LED_RED_Pin|LED_GREEN_Pin|Mems_VL53_xshut_Pin;
  GPIO_InitStruct.Mode = GPIO_MODE_OUTPUT_PP;
  GPIO_InitStruct.Pull = GPIO_NOPULL;
  GPIO_InitStruct.Speed = GPIO_SPEED_FREQ_LOW;
  HAL_GPIO_Init(GPIOH, &GPIO_InitStruct);

  /*Configure GPIO pin : MIC_CCK1_Pin */
  GPIO_InitStruct.Pin = MIC_CCK1_Pin;
  GPIO_InitStruct.Mode = GPIO_MODE_AF_PP;
  GPIO_InitStruct.Pull = GPIO_NOPULL;
  GPIO_InitStruct.Speed = GPIO_SPEED_FREQ_LOW;
  GPIO_InitStruct.Alternate = GPIO_AF6_MDF1;
  HAL_GPIO_Init(MIC_CCK1_GPIO_Port, &GPIO_InitStruct);

  /*Configure GPIO pin : WRLS_WKUP_B_Pin */
  GPIO_InitStruct.Pin = WRLS_WKUP_B_Pin;
  GPIO_InitStruct.Mode = GPIO_MODE_OUTPUT_PP;
  GPIO_InitStruct.Pull = GPIO_NOPULL;
  GPIO_InitStruct.Speed = GPIO_SPEED_FREQ_LOW;
  HAL_GPIO_Init(WRLS_WKUP_B_GPIO_Port, &GPIO_InitStruct);

  /*Configure GPIO pin : ARDUINO_UNO_D14_Pin */
  GPIO_InitStruct.Pin = ARDUINO_UNO_D14_Pin;
  GPIO_InitStruct.Mode = GPIO_MODE_IT_RISING;
  GPIO_InitStruct.Pull = GPIO_NOPULL;
  HAL_GPIO_Init(ARDUINO_UNO_D14_GPIO_Port, &GPIO_InitStruct);

  /*Configure GPIO pins : Mems_VLX_GPIO_Pin Mems_INT_LPS22HH_Pin */
  GPIO_InitStruct.Pin = Mems_VLX_GPIO_Pin|Mems_INT_LPS22HH_Pin;
  GPIO_InitStruct.Mode = GPIO_MODE_INPUT;
  GPIO_InitStruct.Pull = GPIO_NOPULL;
  HAL_GPIO_Init(GPIOG, &GPIO_InitStruct);

  /*Configure GPIO pin : MXCHIP_NOTIFY_Pin */
  GPIO_InitStruct.Pin = MXCHIP_NOTIFY_Pin;
  GPIO_InitStruct.Mode = GPIO_MODE_IT_RISING;
  GPIO_InitStruct.Pull = GPIO_NOPULL;
  HAL_GPIO_Init(MXCHIP_NOTIFY_GPIO_Port, &GPIO_InitStruct);

  /*Configure GPIO pin : USB_UCPD_FLT_Pin */
  GPIO_InitStruct.Pin = USB_UCPD_FLT_Pin;
  GPIO_InitStruct.Mode = GPIO_MODE_IT_FALLING;
  GPIO_InitStruct.Pull = GPIO_PULLUP;
  HAL_GPIO_Init(USB_UCPD_FLT_GPIO_Port, &GPIO_InitStruct);

  /*Configure GPIO pins : Mems_INT_IIS2MDC_Pin USB_IANA_Pin */
  GPIO_InitStruct.Pin = Mems_INT_IIS2MDC_Pin|USB_IANA_Pin;
  GPIO_InitStruct.Mode = GPIO_MODE_INPUT;
  GPIO_InitStruct.Pull = GPIO_NOPULL;
  HAL_GPIO_Init(GPIOD, &GPIO_InitStruct);

  /*Configure GPIO pin : MXCHIP_NSS_Pin */
  GPIO_InitStruct.Pin = MXCHIP_NSS_Pin;
  GPIO_InitStruct.Mode = GPIO_MODE_OUTPUT_PP;
  GPIO_InitStruct.Pull = GPIO_NOPULL;
  GPIO_InitStruct.Speed = GPIO_SPEED_FREQ_HIGH;
  HAL_GPIO_Init(MXCHIP_NSS_GPIO_Port, &GPIO_InitStruct);

  /*Configure GPIO pins : Mems_STSAFE_RESET_Pin MXCHIP_RESET_Pin */
  GPIO_InitStruct.Pin = Mems_STSAFE_RESET_Pin|MXCHIP_RESET_Pin;
  GPIO_InitStruct.Mode = GPIO_MODE_OUTPUT_PP;
  GPIO_InitStruct.Pull = GPIO_NOPULL;
  GPIO_InitStruct.Speed = GPIO_SPEED_FREQ_LOW;
  HAL_GPIO_Init(GPIOF, &GPIO_InitStruct);

  /*Configure GPIO pin : Mems_ISM330DLC_INT1_Pin */
  GPIO_InitStruct.Pin = Mems_ISM330DLC_INT1_Pin;
  GPIO_InitStruct.Mode = GPIO_MODE_INPUT;
  GPIO_InitStruct.Pull = GPIO_NOPULL;
  HAL_GPIO_Init(Mems_ISM330DLC_INT1_GPIO_Port, &GPIO_InitStruct);

  /*Configure GPIO pin : MIC_SDIN0_Pin */
  GPIO_InitStruct.Pin = MIC_SDIN0_Pin;
  GPIO_InitStruct.Mode = GPIO_MODE_AF_PP;
  GPIO_InitStruct.Pull = GPIO_NOPULL;
  GPIO_InitStruct.Speed = GPIO_SPEED_FREQ_LOW;
  GPIO_InitStruct.Alternate = GPIO_AF6_MDF1;
  HAL_GPIO_Init(MIC_SDIN0_GPIO_Port, &GPIO_InitStruct);

  /* EXTI interrupt init*/
  HAL_NVIC_SetPriority(EXTI0_IRQn, 8, 0);
  HAL_NVIC_EnableIRQ(EXTI0_IRQn);

  HAL_NVIC_SetPriority(EXTI8_IRQn, 8, 0);
  HAL_NVIC_EnableIRQ(EXTI8_IRQn);

  HAL_NVIC_SetPriority(EXTI14_IRQn, 8, 0);
  HAL_NVIC_EnableIRQ(EXTI14_IRQn);

  HAL_NVIC_SetPriority(EXTI15_IRQn, 8, 0);
  HAL_NVIC_EnableIRQ(EXTI15_IRQn);

/* USER CODE BEGIN MX_GPIO_Init_2 */

  // Configure MXCHIP_NOTIFY pin (PD14) to generate event on the rising edge
  Driver_GPIO0.Setup          (GPIO_PIN_ID_PORTD(14), GPIO_SignalEvent);
  Driver_GPIO0.SetDirection   (GPIO_PIN_ID_PORTD(14), ARM_GPIO_INPUT);
  Driver_GPIO0.SetEventTrigger(GPIO_PIN_ID_PORTD(14), ARM_GPIO_TRIGGER_RISING_EDGE);

  // Configure MXCHIP_FLOW pin (PG15) to generate event on the rising edge
  Driver_GPIO0.Setup          (GPIO_PIN_ID_PORTG(15), GPIO_SignalEvent);
  Driver_GPIO0.SetDirection   (GPIO_PIN_ID_PORTG(15), ARM_GPIO_INPUT);
  Driver_GPIO0.SetEventTrigger(GPIO_PIN_ID_PORTG(15), ARM_GPIO_TRIGGER_RISING_EDGE);

  // Configure UCPD_FLT pin (PE8) to generate event on the falling edge
  Driver_GPIO0.Setup          (GPIO_PIN_ID_PORTE(8) , GPIO_SignalEvent);
  Driver_GPIO0.SetPullResistor(GPIO_PIN_ID_PORTE(8) , ARM_GPIO_PULL_UP);
  Driver_GPIO0.SetDirection   (GPIO_PIN_ID_PORTE(8) , ARM_GPIO_INPUT);
  Driver_GPIO0.SetEventTrigger(GPIO_PIN_ID_PORTE(8) , ARM_GPIO_TRIGGER_FALLING_EDGE);

/* USER CODE END MX_GPIO_Init_2 */
}

void HAL_TIM_PeriodElapsedCallback(TIM_HandleTypeDef *htim)
{
  if (htim->Instance == TIM17) {
    HAL_IncTick();
  }
}

void Error_Handler(void)
{
  __disable_irq();
  while (1)
  {
  }
}
